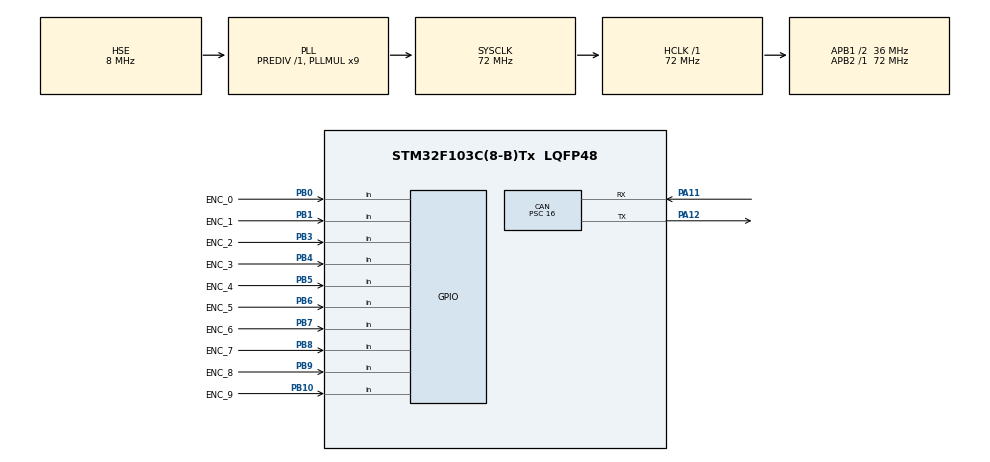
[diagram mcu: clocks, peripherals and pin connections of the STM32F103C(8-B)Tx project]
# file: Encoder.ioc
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CAN.BS1=CAN_BS1_15TQ
CAN.BS2=CAN_BS2_2TQ
CAN.CalculateBaudRate=125000
CAN.CalculateTimeBit=8000
CAN.CalculateTimeQuantum=444.44444444444446
CAN.Prescaler=16
Mcu.Family=STM32F1
Mcu.Name=STM32F103C(8-B)Tx
Mcu.Package=LQFP48
NVIC.PriorityGroup=NVIC_PRIORITYGROUP_4
NVIC.TIM3_IRQn=true\:15\:0\:false\:false\:true\:false\:true\:true
NVIC.TimeBase=TIM3_IRQn
NVIC.TimeBaseIP=TIM3
PA11.Mode=CAN_Activate
PA11.Signal=CAN_RX
PA12.Mode=CAN_Activate
PA12.Signal=CAN_TX
PA13.Mode=Serial_Wire
PA13.Signal=SYS_JTMS-SWDIO
PA14.Mode=Serial_Wire
PA14.Signal=SYS_JTCK-SWCLK
PB0.GPIO_Label=ENC_0
PB0.GPIO_PuPd=GPIO_PULLUP
PB0.Signal=GPIO_Input
PB1.GPIO_Label=ENC_1
PB1.GPIO_PuPd=GPIO_PULLUP
PB1.Signal=GPIO_Input
PB10.GPIO_Label=ENC_9
PB10.GPIO_PuPd=GPIO_PULLUP
PB10.Signal=GPIO_Input
PB3.GPIO_Label=ENC_2
PB3.GPIO_PuPd=GPIO_PULLUP
PB3.Signal=GPIO_Input
PB4.GPIO_Label=ENC_3
PB4.GPIO_PuPd=GPIO_PULLUP
PB4.Signal=GPIO_Input
PB5.GPIO_Label=ENC_4
PB5.GPIO_PuPd=GPIO_PULLUP
PB5.Signal=GPIO_Input
PB6.GPIO_Label=ENC_5
PB6.GPIO_PuPd=GPIO_PULLUP
PB6.Signal=GPIO_Input
PB7.GPIO_Label=ENC_6
PB7.GPIO_PuPd=GPIO_PULLUP
PB7.Signal=GPIO_Input
PB8.GPIO_Label=ENC_7
PB8.GPIO_PuPd=GPIO_PULLUP
PB8.Signal=GPIO_Input
PB9.GPIO_Label=ENC_8
PB9.GPIO_PuPd=GPIO_PULLUP
PB9.Signal=GPIO_Input
PD0-OSC_IN.Mode=HSE-External-Oscillator
PD0-OSC_IN.Signal=RCC_OSC_IN
PD1-OSC_OUT.Mode=HSE-External-Oscillator
PD1-OSC_OUT.Signal=RCC_OSC_OUT
ProjectManager.HeapSize=0x200
ProjectManager.StackSize=0x400
ProjectManager.TargetToolchain=STM32CubeIDE
RCC.AHBFreq_Value=72000000
RCC.APB1CLKDivider=RCC_HCLK_DIV2
RCC.APB1Freq_Value=36000000
RCC.APB1TimFreq_Value=72000000
RCC.APB2Freq_Value=72000000
RCC.APB2TimFreq_Value=72000000
RCC.HCLKFreq_Value=72000000
RCC.PLLMUL=RCC_PLL_MUL9
RCC.PLLSourceVirtual=RCC_PLLSOURCE_HSE
RCC.SYSCLKFreq_VALUE=72000000
RCC.SYSCLKSource=RCC_SYSCLKSOURCE_PLLCLK
RCC.USBFreq_Value=72000000
TIM2.Prescaler=71
VP_SYS_VS_tim3.Mode=TIM3
VP_TIM2_VS_ClockSourceINT.Mode=Internal
board=custom

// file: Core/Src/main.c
/* USER CODE BEGIN Header */
/**
  ******************************************************************************
  * @file           : main.c
  * @brief          : Main program body
  ******************************************************************************
  * @attention
  *
  * Copyright (c) 2026 STMicroelectronics.
  * All rights reserved.
  *
  * This software is licensed under terms that can be found in the LICENSE file
  * in the root directory of this software component.
  * If no LICENSE file comes with this software, it is provided AS-IS.
  *
  ******************************************************************************
  */
/* USER CODE END Header */
#include "main.h"
#include "can.h"
#include "tim.h"
#include "gpio.h"

/* USER CODE BEGIN Includes */
/*============================= Files Includes =============================*/
#include "Encoder.h"
/*==========================================================================*/
/* USER CODE END Includes */

/* USER CODE BEGIN PV */
/*============================= Private variables =============================*/
TaskHandle_t Encoder_main_task;
/*=============================================================================*/
/* USER CODE END PV */

void SystemClock_Config(void);

int main(void)
{

  /* MCU Configuration--------------------------------------------------------*/

  /* Reset of all peripherals, Initializes the Flash interface and the Systick. */
  HAL_Init();

  /* Configure the system clock */
  SystemClock_Config();

  /* Initialize all configured peripherals */
  MX_GPIO_Init();
  MX_CAN_Init();
  MX_TIM2_Init();
  /* USER CODE BEGIN 2 */
  // start TIM2 for delays in us
  HAL_TIM_Base_Start(&htim2);

  // task creation
  xTaskCreate(Encoder_Task, "Encoder main task", 256, NULL, 5, &Encoder_main_task);

  // start the scheduler
  vTaskStartScheduler();

  /* USER CODE END 2 */

  /* Infinite loop */
  while (1)
  {

  }
}

void SystemClock_Config(void)
{
  RCC_OscInitTypeDef RCC_OscInitStruct = {0};
  RCC_ClkInitTypeDef RCC_ClkInitStruct = {0};

  /** Initializes the RCC Oscillators according to the specified parameters
  * in the RCC_OscInitTypeDef structure.
  */
  RCC_OscInitStruct.OscillatorType = RCC_OSCILLATORTYPE_HSE;
  RCC_OscInitStruct.HSEState = RCC_HSE_ON;
  RCC_OscInitStruct.HSEPredivValue = RCC_HSE_PREDIV_DIV1;
  RCC_OscInitStruct.HSIState = RCC_HSI_ON;
  RCC_OscInitStruct.PLL.PLLState = RCC_PLL_ON;
  RCC_OscInitStruct.PLL.PLLSource = RCC_PLLSOURCE_HSE;
  RCC_OscInitStruct.PLL.PLLMUL = RCC_PLL_MUL9;
  if (HAL_RCC_OscConfig(&RCC_OscInitStruct) != HAL_OK)
  {
    Error_Handler();
  }

  /** Initializes the CPU, AHB and APB buses clocks
  */
  RCC_ClkInitStruct.ClockType = RCC_CLOCKTYPE_HCLK|RCC_CLOCKTYPE_SYSCLK
                              |RCC_CLOCKTYPE_PCLK1|RCC_CLOCKTYPE_PCLK2;
  RCC_ClkInitStruct.SYSCLKSource = RCC_SYSCLKSOURCE_PLLCLK;
  RCC_ClkInitStruct.AHBCLKDivider = RCC_SYSCLK_DIV1;
  RCC_ClkInitStruct.APB1CLKDivider = RCC_HCLK_DIV2;
  RCC_ClkInitStruct.APB2CLKDivider = RCC_HCLK_DIV1;

  if (HAL_RCC_ClockConfig(&RCC_ClkInitStruct, FLASH_LATENCY_2) != HAL_OK)
  {
    Error_Handler();
  }
}

void HAL_TIM_PeriodElapsedCallback(TIM_HandleTypeDef *htim)
{
  if (htim->Instance == TIM3)
  {
    HAL_IncTick();
  }
}

void Error_Handler(void)
{
  __disable_irq();
  while (1)
  {
  }
}
